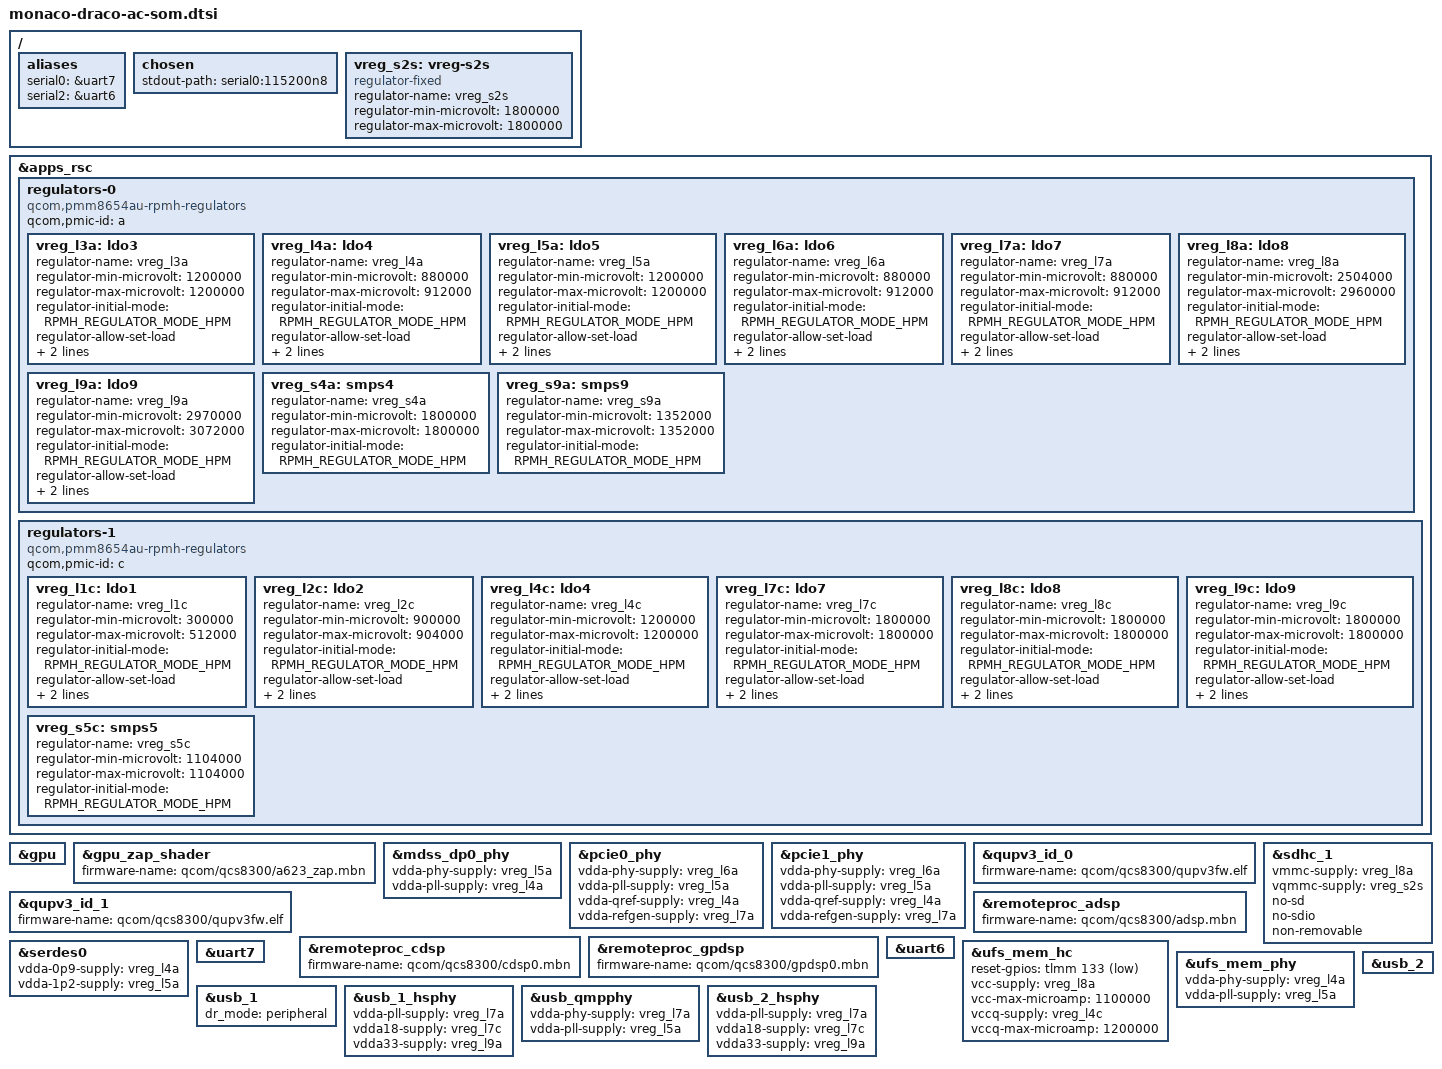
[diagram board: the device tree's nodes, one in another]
// SPDX-License-Identifier: BSD-3-Clause
/*
 * Copyright (c) Qualcomm Technologies, Inc. and/or its subsidiaries.
 */

#include <dt-bindings/gpio/gpio.h>
#include <dt-bindings/regulator/qcom,rpmh-regulator.h>

#include "monaco.dtsi"
#include "monaco-pmics.dtsi"

/ {
	aliases {
		serial0 = &uart7;
		serial2 = &uart6;
	};

	chosen {
		stdout-path = "serial0:115200n8";
	};

	/* This comes from a PMIC handled within the SAIL domain */
	vreg_s2s: vreg-s2s {
		compatible = "regulator-fixed";
		regulator-name = "vreg_s2s";

		regulator-min-microvolt = <1800000>;
		regulator-max-microvolt = <1800000>;
	};
};

&apps_rsc {
	regulators-0 {
		compatible = "qcom,pmm8654au-rpmh-regulators";
		qcom,pmic-id = "a";

		vreg_l3a: ldo3 {
			regulator-name = "vreg_l3a";
			regulator-min-microvolt = <1200000>;
			regulator-max-microvolt = <1200000>;
			regulator-initial-mode = <RPMH_REGULATOR_MODE_HPM>;
			regulator-allow-set-load;
			regulator-allowed-modes = <RPMH_REGULATOR_MODE_HPM>;
		};

		vreg_l4a: ldo4 {
			regulator-name = "vreg_l4a";
			regulator-min-microvolt = <880000>;
			regulator-max-microvolt = <912000>;
			regulator-initial-mode = <RPMH_REGULATOR_MODE_HPM>;
			regulator-allow-set-load;
			regulator-allowed-modes = <RPMH_REGULATOR_MODE_HPM>;
		};

		vreg_l5a: ldo5 {
			regulator-name = "vreg_l5a";
			regulator-min-microvolt = <1200000>;
			regulator-max-microvolt = <1200000>;
			regulator-initial-mode = <RPMH_REGULATOR_MODE_HPM>;
			regulator-allow-set-load;
			regulator-allowed-modes = <RPMH_REGULATOR_MODE_HPM>;
		};

		vreg_l6a: ldo6 {
			regulator-name = "vreg_l6a";
			regulator-min-microvolt = <880000>;
			regulator-max-microvolt = <912000>;
			regulator-initial-mode = <RPMH_REGULATOR_MODE_HPM>;
			regulator-allow-set-load;
			regulator-allowed-modes = <RPMH_REGULATOR_MODE_HPM>;
		};

		vreg_l7a: ldo7 {
			regulator-name = "vreg_l7a";
			regulator-min-microvolt = <880000>;
			regulator-max-microvolt = <912000>;
			regulator-initial-mode = <RPMH_REGULATOR_MODE_HPM>;
			regulator-allow-set-load;
			regulator-allowed-modes = <RPMH_REGULATOR_MODE_HPM>;
		};

		vreg_l8a: ldo8 {
			regulator-name = "vreg_l8a";
			regulator-min-microvolt = <2504000>;
			regulator-max-microvolt = <2960000>;
			regulator-initial-mode = <RPMH_REGULATOR_MODE_HPM>;
			regulator-allow-set-load;
			regulator-allowed-modes = <RPMH_REGULATOR_MODE_HPM>;
		};

		vreg_l9a: ldo9 {
			regulator-name = "vreg_l9a";
			regulator-min-microvolt = <2970000>;
			regulator-max-microvolt = <3072000>;
			regulator-initial-mode = <RPMH_REGULATOR_MODE_HPM>;
			regulator-allow-set-load;
			regulator-allowed-modes = <RPMH_REGULATOR_MODE_HPM>;
		};

		vreg_s4a: smps4 {
			regulator-name = "vreg_s4a";
			regulator-min-microvolt = <1800000>;
			regulator-max-microvolt = <1800000>;
			regulator-initial-mode = <RPMH_REGULATOR_MODE_HPM>;
		};

		vreg_s9a: smps9 {
			regulator-name = "vreg_s9a";
			regulator-min-microvolt = <1352000>;
			regulator-max-microvolt = <1352000>;
			regulator-initial-mode = <RPMH_REGULATOR_MODE_HPM>;
		};
	};

	regulators-1 {
		compatible = "qcom,pmm8654au-rpmh-regulators";
		qcom,pmic-id = "c";

		vreg_l1c: ldo1 {
			regulator-name = "vreg_l1c";
			regulator-min-microvolt = <300000>;
			regulator-max-microvolt = <512000>;
			regulator-initial-mode = <RPMH_REGULATOR_MODE_HPM>;
			regulator-allow-set-load;
			regulator-allowed-modes = <RPMH_REGULATOR_MODE_HPM>;
		};

		vreg_l2c: ldo2 {
			regulator-name = "vreg_l2c";
			regulator-min-microvolt = <900000>;
			regulator-max-microvolt = <904000>;
			regulator-initial-mode = <RPMH_REGULATOR_MODE_HPM>;
			regulator-allow-set-load;
			regulator-allowed-modes = <RPMH_REGULATOR_MODE_HPM>;
		};

		vreg_l4c: ldo4 {
			regulator-name = "vreg_l4c";
			regulator-min-microvolt = <1200000>;
			regulator-max-microvolt = <1200000>;
			regulator-initial-mode = <RPMH_REGULATOR_MODE_HPM>;
			regulator-allow-set-load;
			regulator-allowed-modes = <RPMH_REGULATOR_MODE_HPM>;
		};

		vreg_l7c: ldo7 {
			regulator-name = "vreg_l7c";
			regulator-min-microvolt = <1800000>;
			regulator-max-microvolt = <1800000>;
			regulator-initial-mode = <RPMH_REGULATOR_MODE_HPM>;
			regulator-allow-set-load;
			regulator-allowed-modes = <RPMH_REGULATOR_MODE_HPM>;
		};

		vreg_l8c: ldo8 {
			regulator-name = "vreg_l8c";
			regulator-min-microvolt = <1800000>;
			regulator-max-microvolt = <1800000>;
			regulator-initial-mode = <RPMH_REGULATOR_MODE_HPM>;
			regulator-allow-set-load;
			regulator-allowed-modes = <RPMH_REGULATOR_MODE_HPM>;
		};

		vreg_l9c: ldo9 {
			regulator-name = "vreg_l9c";
			regulator-min-microvolt = <1800000>;
			regulator-max-microvolt = <1800000>;
			regulator-initial-mode = <RPMH_REGULATOR_MODE_HPM>;
			regulator-allow-set-load;
			regulator-allowed-modes = <RPMH_REGULATOR_MODE_HPM>;
		};

		vreg_s5c: smps5 {
			regulator-name = "vreg_s5c";
			regulator-min-microvolt = <1104000>;
			regulator-max-microvolt = <1104000>;
			regulator-initial-mode = <RPMH_REGULATOR_MODE_HPM>;
		};
	};
};

&gpu {
	status = "okay";
};

&gpu_zap_shader {
	firmware-name = "qcom/qcs8300/a623_zap.mbn";
};

&mdss_dp0_phy {
	vdda-phy-supply = <&vreg_l5a>;
	vdda-pll-supply = <&vreg_l4a>;

	status = "okay";
};

&pcie0_phy {
	vdda-phy-supply = <&vreg_l6a>;
	vdda-pll-supply = <&vreg_l5a>;
	vdda-qref-supply = <&vreg_l4a>;
	vdda-refgen-supply = <&vreg_l7a>;

	status = "okay";
};

&pcie1_phy {
	vdda-phy-supply = <&vreg_l6a>;
	vdda-pll-supply = <&vreg_l5a>;
	vdda-qref-supply = <&vreg_l4a>;
	vdda-refgen-supply = <&vreg_l7a>;

	status = "okay";
};

&qupv3_id_0 {
	firmware-name = "qcom/qcs8300/qupv3fw.elf";

	status = "okay";
};

&qupv3_id_1 {
	firmware-name = "qcom/qcs8300/qupv3fw.elf";

	status = "okay";
};

&remoteproc_adsp {
	firmware-name = "qcom/qcs8300/adsp.mbn";

	status = "okay";
};

&remoteproc_cdsp {
	firmware-name = "qcom/qcs8300/cdsp0.mbn";

	status = "okay";
};

&remoteproc_gpdsp {
	firmware-name = "qcom/qcs8300/gpdsp0.mbn";

	status = "okay";
};

&sdhc_1 {
	vmmc-supply = <&vreg_l8a>;
	vqmmc-supply = <&vreg_s2s>;

	no-sd;
	no-sdio;
	non-removable;

	status = "okay";
};

&serdes0 {
	vdda-0p9-supply = <&vreg_l4a>;
	vdda-1p2-supply = <&vreg_l5a>;

	status = "okay";
};

&uart6 {
	status = "okay";
};

&uart7 {
	status = "okay";
};

&ufs_mem_hc {
	reset-gpios = <&tlmm 133 GPIO_ACTIVE_LOW>;
	vcc-supply = <&vreg_l8a>;
	vcc-max-microamp = <1100000>;
	vccq-supply = <&vreg_l4c>;
	vccq-max-microamp = <1200000>;

	status = "okay";
};

&ufs_mem_phy {
	vdda-phy-supply = <&vreg_l4a>;
	vdda-pll-supply = <&vreg_l5a>;

	status = "okay";
};

&usb_1 {
	dr_mode = "peripheral";

	status = "okay";
};

&usb_1_hsphy {
	vdda-pll-supply = <&vreg_l7a>;
	vdda18-supply = <&vreg_l7c>;
	vdda33-supply = <&vreg_l9a>;

	status = "okay";
};

&usb_qmpphy {
	vdda-phy-supply = <&vreg_l7a>;
	vdda-pll-supply = <&vreg_l5a>;

	status = "okay";
};

&usb_2 {
	status = "okay";
};

&usb_2_hsphy {
	vdda-pll-supply = <&vreg_l7a>;
	vdda18-supply = <&vreg_l7c>;
	vdda33-supply = <&vreg_l9a>;

	status = "okay";
};
